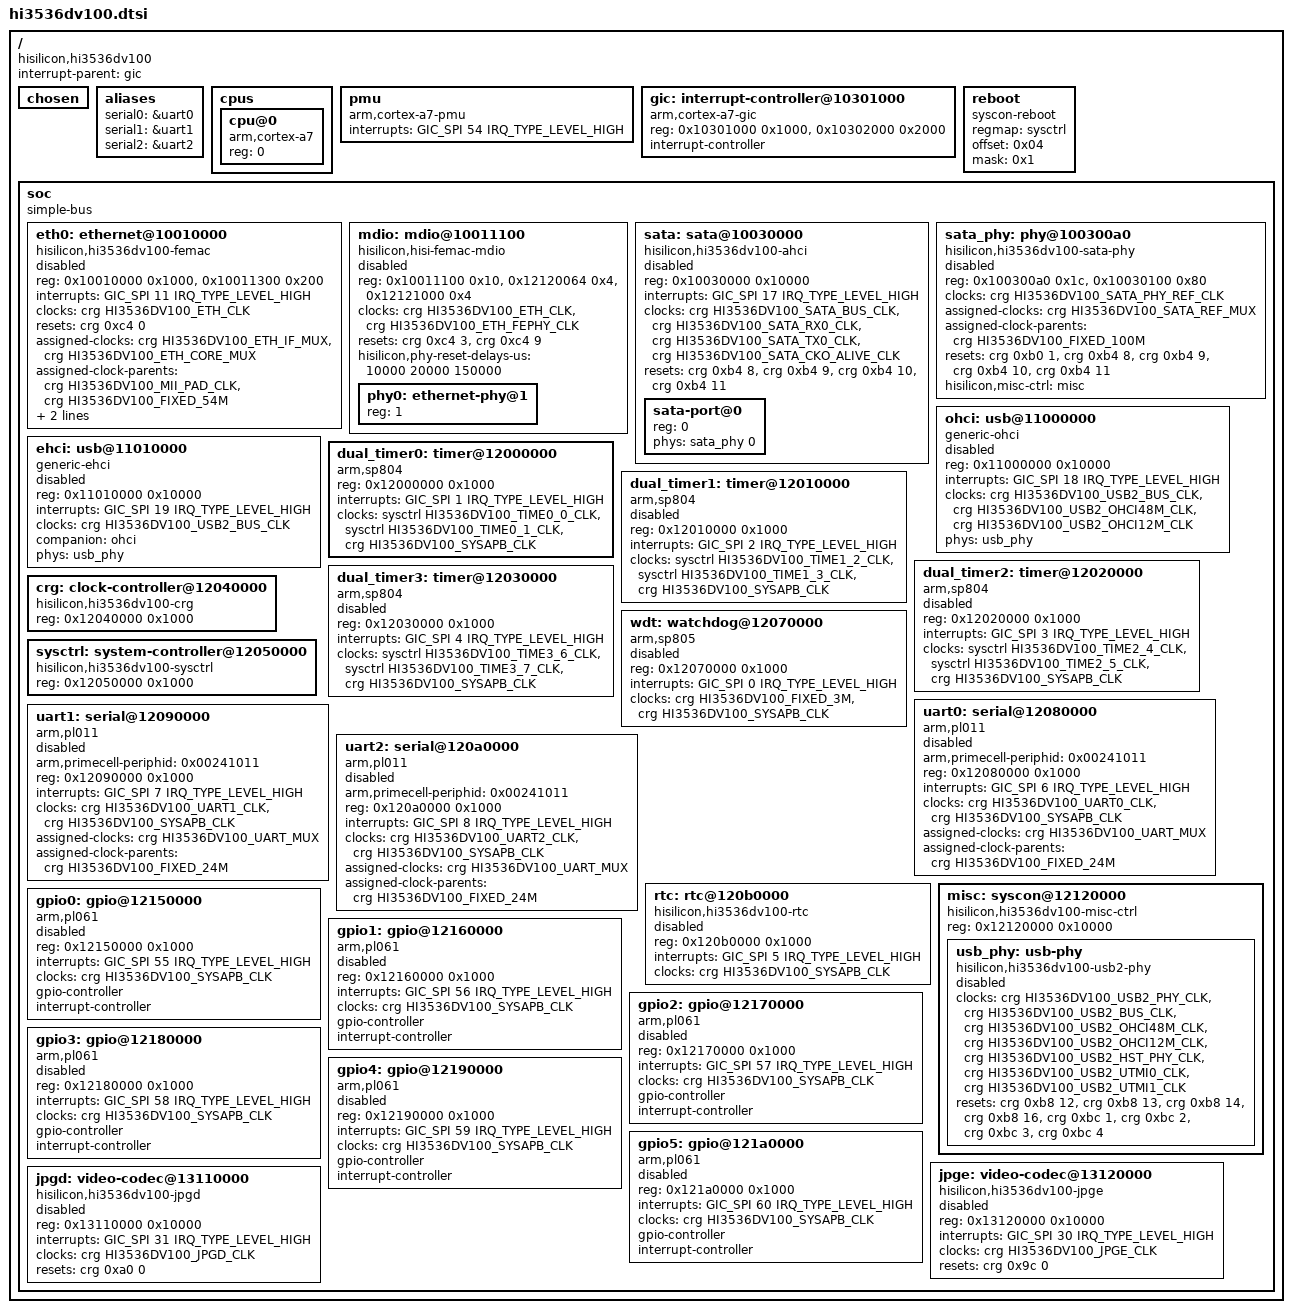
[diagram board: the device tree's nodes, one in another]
// SPDX-License-Identifier: GPL-2.0-or-later
/*
 * HiSilicon Hi3536D V100 SoC (NVR decoder, one Cortex-A7, GIC-400, DDR at
 * 0x80000000). The Hi3536E reports the same SCSYSID and is described by this
 * file too: the OpenIPC U-Boot sets other CPU and DDR PLL values for it and
 * reports SC_SYSID0 as 0x02000000 (a Hi3536D V100 board reads 0x01000000),
 * nothing else is known.
 *
 * Addresses and interrupts are those of the Hi3536D V100 data sheet (address
 * space mapping of chapter 2 and the interrupt table of chapter 3.4, where an
 * interrupt bit n is SPI n - 32). This file describes only the blocks that
 * have a binding and a driver and whose clocks and resets the CRG provides:
 * the other blocks (flash controller, DMA, media) follow with their
 * drivers, using the clock identifiers and reset bits of
 * hi3536dv100-clock.h.
 *
 * The Cortex-A7 generic timer is not described: no document gives the
 * frequency of its counter input, and on a Hi3536D V100 board CNTFRQ reads 0
 * and the counter stays at 0, so the SP804 timer is the only tick source.
 */

#include <dt-bindings/clock/hi3536dv100-clock.h>
#include <dt-bindings/interrupt-controller/arm-gic.h>

/ {
	compatible = "hisilicon,hi3536dv100";
	#address-cells = <1>;
	#size-cells = <1>;
	interrupt-parent = <&gic>;
	chosen { };

	aliases {
		serial0 = &uart0;
		serial1 = &uart1;
		serial2 = &uart2;
	};

	cpus {
		#address-cells = <1>;
		#size-cells = <0>;

		cpu@0 {
			device_type = "cpu";
			compatible = "arm,cortex-a7";
			reg = <0>;
		};
	};

	/* interrupt bit 86 (A7_PMUIRQ) */
	pmu {
		compatible = "arm,cortex-a7-pmu";
		interrupts = <GIC_SPI 54 IRQ_TYPE_LEVEL_HIGH>;
	};

	/* the GICC window is 0x2000 as in every GIC-400, the vendor tree maps 0x100 */
	gic: interrupt-controller@10301000 {
		compatible = "arm,cortex-a7-gic";
		reg = <0x10301000 0x1000>,	/* distributor */
		      <0x10302000 0x2000>;	/* CPU interface */
		#interrupt-cells = <3>;
		interrupt-controller;
	};

	/* SC_SYSRES is write protected by SC_LOCKEN */
	reboot {
		compatible = "syscon-reboot";
		regmap = <&sysctrl>;
		offset = <0x04>;	/* SC_SYSRES */
		mask = <0x1>;
	};

	soc {
		#address-cells = <1>;
		#size-cells = <1>;
		compatible = "simple-bus";
		ranges;

		/*
		 * The Fast Ethernet MAC (hisi-femac) with the MDIO controller, the
		 * internal FE PHY and the global MAC registers at +0x1300. The clock
		 * muxes are programmed here instead of relying on the boot loader:
		 * MII pads (the internal PHY is MII only) and the 54 MHz MAC core
		 * clock. The MDIO controller owns the PHY clock and the PHY reset;
		 * the internal/external PHY select (MISC_CTRL25 bit 5) is not set
		 * by this node, the MDIO driver handles it.
		 * A board that wires an external PHY replaces the PHY node, the
		 * phy-mode and the interface mux.
		 */
		eth0: ethernet@10010000 {
			compatible = "hisilicon,hi3536dv100-femac",
				     "hisilicon,hisi-femac-v2";
			reg = <0x10010000 0x1000>, <0x10011300 0x200>;
			interrupts = <GIC_SPI 11 IRQ_TYPE_LEVEL_HIGH>;
			clocks = <&crg HI3536DV100_ETH_CLK>;
			resets = <&crg 0xc4 0>;
			reset-names = "mac";
			assigned-clocks = <&crg HI3536DV100_ETH_IF_MUX>,
					  <&crg HI3536DV100_ETH_CORE_MUX>;
			assigned-clock-parents = <&crg HI3536DV100_MII_PAD_CLK>,
						 <&crg HI3536DV100_FIXED_54M>;
			phy-mode = "mii";
			phy-handle = <&phy0>;
			status = "disabled";
		};

		/*
		 * MDIO, then the control register of the internal PHY (MISC_CTRL25:
		 * bit 5 clear selects the internal PHY, bits 4:0 are its address) and its
		 * trim value (FEPHY_TRIM). The resets are PERI_CRG49 bit 3 (external
		 * PHY) and bit 9 (internal PHY); the driver resets and trims the
		 * internal PHY at probe time.
		 */
		mdio: mdio@10011100 {
			compatible = "hisilicon,hisi-femac-mdio";
			reg = <0x10011100 0x10>, <0x12120064 0x4>, <0x12121000 0x4>;
			clocks = <&crg HI3536DV100_ETH_CLK>,
				 <&crg HI3536DV100_ETH_FEPHY_CLK>;
			clock-names = "mdio", "phy";
			resets = <&crg 0xc4 3>, <&crg 0xc4 9>;
			reset-names = "external-phy", "internal-phy";
			hisilicon,phy-reset-delays-us = <10000 20000 150000>;
			#address-cells = <1>;
			#size-cells = <0>;
			status = "disabled";

			phy0: ethernet-phy@1 {
				reg = <1>;
			};
		};

		/*
		 * AHCI SATA controller with one port. The clocks and resets are
		 * those of PERI_CRG45, the PHY registers inside its window belong
		 * to the PHY node. The PI register may read 0xf: the sub-node of
		 * the port limits the implemented ports to port 0.
		 */
		sata: sata@10030000 {
			compatible = "hisilicon,hi3536dv100-ahci", "generic-ahci";
			reg = <0x10030000 0x10000>;
			interrupts = <GIC_SPI 17 IRQ_TYPE_LEVEL_HIGH>;
			clocks = <&crg HI3536DV100_SATA_BUS_CLK>,
				 <&crg HI3536DV100_SATA_RX0_CLK>,
				 <&crg HI3536DV100_SATA_TX0_CLK>,
				 <&crg HI3536DV100_SATA_CKO_ALIVE_CLK>;
			resets = <&crg 0xb4 8>, <&crg 0xb4 9>, <&crg 0xb4 10>,
				 <&crg 0xb4 11>;
			#address-cells = <1>;
			#size-cells = <0>;
			status = "disabled";

			sata-port@0 {
				reg = <0>;
				phys = <&sata_phy 0>;
			};
		};

		/*
		 * The PHY registers inside the AHCI window. The reference clock
		 * is 100 MHz, set here instead of relying on the boot loader
		 * (the register reads 100 MHz after a reset). The PHY pulses
		 * the four controller resets that it shares with the AHCI node.
		 */
		sata_phy: phy@100300a0 {
			compatible = "hisilicon,hi3536dv100-sata-phy";
			reg = <0x100300a0 0x1c>, <0x10030100 0x80>;
			reg-names = "ctrl", "ports";
			#phy-cells = <1>;
			clocks = <&crg HI3536DV100_SATA_PHY_REF_CLK>;
			clock-names = "ref";
			assigned-clocks = <&crg HI3536DV100_SATA_REF_MUX>;
			assigned-clock-parents = <&crg HI3536DV100_FIXED_100M>;
			resets = <&crg 0xb0 1>, <&crg 0xb4 8>, <&crg 0xb4 9>,
				 <&crg 0xb4 10>, <&crg 0xb4 11>;
			reset-names = "lane", "ctrl-bus", "ctrl-alive",
				      "ctrl-rx0", "ctrl-sata0";
			hisilicon,misc-ctrl = <&misc>;
			status = "disabled";
		};

		/*
		 * USB 2.0 host: one OHCI and one EHCI on two ports (the OHCI is the
		 * companion of the EHCI: full and low speed devices go to it). The clock
		 * gates, the resets and the start sequence belong to the PHY node (the
		 * MISC_CTRL child below); the controllers list the gates they run from. A
		 * board file enables the PHY and the controllers it wires.
		 */
		ohci: usb@11000000 {
			compatible = "generic-ohci";
			reg = <0x11000000 0x10000>;
			interrupts = <GIC_SPI 18 IRQ_TYPE_LEVEL_HIGH>;
			clocks = <&crg HI3536DV100_USB2_BUS_CLK>,
				 <&crg HI3536DV100_USB2_OHCI48M_CLK>,
				 <&crg HI3536DV100_USB2_OHCI12M_CLK>;
			phys = <&usb_phy>;
			phy-names = "usb";
			status = "disabled";
		};

		ehci: usb@11010000 {
			compatible = "generic-ehci";
			reg = <0x11010000 0x10000>;
			interrupts = <GIC_SPI 19 IRQ_TYPE_LEVEL_HIGH>;
			clocks = <&crg HI3536DV100_USB2_BUS_CLK>;
			companion = <&ohci>;
			phys = <&usb_phy>;
			phy-names = "usb";
			status = "disabled";
		};

		/*
		 * The four SP804 pairs: the count clocks are selected in SC_CTRL (3 MHz or
		 * the system APB clock) and provided by the system controller.
		 */
		dual_timer0: timer@12000000 {
			compatible = "arm,sp804", "arm,primecell";
			reg = <0x12000000 0x1000>;
			interrupts = <GIC_SPI 1 IRQ_TYPE_LEVEL_HIGH>;
			clocks = <&sysctrl HI3536DV100_TIME0_0_CLK>,
				 <&sysctrl HI3536DV100_TIME0_1_CLK>,
				 <&crg HI3536DV100_SYSAPB_CLK>;
			clock-names = "timer0", "timer1", "apb_pclk";
		};

		dual_timer1: timer@12010000 {
			compatible = "arm,sp804", "arm,primecell";
			reg = <0x12010000 0x1000>;
			interrupts = <GIC_SPI 2 IRQ_TYPE_LEVEL_HIGH>;
			clocks = <&sysctrl HI3536DV100_TIME1_2_CLK>,
				 <&sysctrl HI3536DV100_TIME1_3_CLK>,
				 <&crg HI3536DV100_SYSAPB_CLK>;
			clock-names = "timer2", "timer3", "apb_pclk";
			status = "disabled";
		};

		dual_timer2: timer@12020000 {
			compatible = "arm,sp804", "arm,primecell";
			reg = <0x12020000 0x1000>;
			interrupts = <GIC_SPI 3 IRQ_TYPE_LEVEL_HIGH>;
			clocks = <&sysctrl HI3536DV100_TIME2_4_CLK>,
				 <&sysctrl HI3536DV100_TIME2_5_CLK>,
				 <&crg HI3536DV100_SYSAPB_CLK>;
			clock-names = "timer4", "timer5", "apb_pclk";
			status = "disabled";
		};

		dual_timer3: timer@12030000 {
			compatible = "arm,sp804", "arm,primecell";
			reg = <0x12030000 0x1000>;
			interrupts = <GIC_SPI 4 IRQ_TYPE_LEVEL_HIGH>;
			clocks = <&sysctrl HI3536DV100_TIME3_6_CLK>,
				 <&sysctrl HI3536DV100_TIME3_7_CLK>,
				 <&crg HI3536DV100_SYSAPB_CLK>;
			clock-names = "timer6", "timer7", "apb_pclk";
			status = "disabled";
		};

		crg: clock-controller@12040000 {
			compatible = "hisilicon,hi3536dv100-crg";
			reg = <0x12040000 0x1000>;
			#clock-cells = <1>;
			#reset-cells = <2>;
		};

		/* SC_CTRL, SC_SYSRES (0x04), SC_SYSSTAT (0x8c), SC_SYSID0..3 (0xee0) */
		sysctrl: system-controller@12050000 {
			compatible = "hisilicon,hi3536dv100-sysctrl", "syscon";
			reg = <0x12050000 0x1000>;
			#clock-cells = <1>;
		};

		/* the watchdog counts a 3 MHz clock */
		wdt: watchdog@12070000 {
			compatible = "arm,sp805", "arm,primecell";
			reg = <0x12070000 0x1000>;
			interrupts = <GIC_SPI 0 IRQ_TYPE_LEVEL_HIGH>;
			clocks = <&crg HI3536DV100_FIXED_3M>,
				 <&crg HI3536DV100_SYSAPB_CLK>;
			clock-names = "wdog_clk", "apb_pclk";
			status = "disabled";
		};

		/*
		 * The three UARTs share the clock select of PERI_CRG51: it is set to the
		 * 24 MHz crystal here instead of relying on the boot loader.
		 */
		uart0: serial@12080000 {
			compatible = "arm,pl011", "arm,primecell";
			arm,primecell-periphid = <0x00241011>;
			reg = <0x12080000 0x1000>;
			interrupts = <GIC_SPI 6 IRQ_TYPE_LEVEL_HIGH>;
			clocks = <&crg HI3536DV100_UART0_CLK>,
				 <&crg HI3536DV100_SYSAPB_CLK>;
			clock-names = "uartclk", "apb_pclk";
			assigned-clocks = <&crg HI3536DV100_UART_MUX>;
			assigned-clock-parents = <&crg HI3536DV100_FIXED_24M>;
			status = "disabled";
		};

		uart1: serial@12090000 {
			compatible = "arm,pl011", "arm,primecell";
			arm,primecell-periphid = <0x00241011>;
			reg = <0x12090000 0x1000>;
			interrupts = <GIC_SPI 7 IRQ_TYPE_LEVEL_HIGH>;
			clocks = <&crg HI3536DV100_UART1_CLK>,
				 <&crg HI3536DV100_SYSAPB_CLK>;
			clock-names = "uartclk", "apb_pclk";
			assigned-clocks = <&crg HI3536DV100_UART_MUX>;
			assigned-clock-parents = <&crg HI3536DV100_FIXED_24M>;
			status = "disabled";
		};

		uart2: serial@120a0000 {
			compatible = "arm,pl011", "arm,primecell";
			arm,primecell-periphid = <0x00241011>;
			reg = <0x120a0000 0x1000>;
			interrupts = <GIC_SPI 8 IRQ_TYPE_LEVEL_HIGH>;
			clocks = <&crg HI3536DV100_UART2_CLK>,
				 <&crg HI3536DV100_SYSAPB_CLK>;
			clock-names = "uartclk", "apb_pclk";
			assigned-clocks = <&crg HI3536DV100_UART_MUX>;
			assigned-clock-parents = <&crg HI3536DV100_FIXED_24M>;
			status = "disabled";
		};

		/*
		 * The RTC macro sits behind an SPI bridge whose divider the driver
		 * derives from the system APB clock (the bridge clock is 5 MHz at
		 * most). The alarm interrupt is bit 37 of the interrupt table. The
		 * macro has its own supply pin (AVDD_BAT) and a 32.768 kHz crystal,
		 * so a board enables the node when it fits them.
		 */
		rtc: rtc@120b0000 {
			compatible = "hisilicon,hi3536dv100-rtc",
				     "hisilicon,hisi-spi-rtc-v3";
			reg = <0x120b0000 0x1000>;
			interrupts = <GIC_SPI 5 IRQ_TYPE_LEVEL_HIGH>;
			clocks = <&crg HI3536DV100_SYSAPB_CLK>;
			status = "disabled";
		};

		/*
		 * MISC_CTRL: the USB 2.0 control words and PHY registers (offset
		 * 0x8000) and the SATA PHY parameters now, the FE PHY controls and
		 * the DDR master priorities later.
		 */
		misc: syscon@12120000 {
			compatible = "hisilicon,hi3536dv100-misc-ctrl", "syscon", "simple-mfd";
			reg = <0x12120000 0x10000>;

			/*
			 * The start sequence drives PERI_CRG46 and PERI_CRG47 (reset bits
			 * 12 to 14 and 16 of 0xb8, 1 to 4 of 0xbc) and programs the
			 * controller control word, so nothing is left to the boot loader.
			 */
			usb_phy: usb-phy {
				compatible = "hisilicon,hi3536dv100-usb2-phy";
				#phy-cells = <0>;
				clocks = <&crg HI3536DV100_USB2_PHY_CLK>,
					 <&crg HI3536DV100_USB2_BUS_CLK>,
					 <&crg HI3536DV100_USB2_OHCI48M_CLK>,
					 <&crg HI3536DV100_USB2_OHCI12M_CLK>,
					 <&crg HI3536DV100_USB2_HST_PHY_CLK>,
					 <&crg HI3536DV100_USB2_UTMI0_CLK>,
					 <&crg HI3536DV100_USB2_UTMI1_CLK>;
				clock-names = "ref", "bus", "ohci48m", "ohci12m",
					      "hst-phy", "utmi0", "utmi1";
				resets = <&crg 0xb8 12>, <&crg 0xb8 13>,
					 <&crg 0xb8 14>, <&crg 0xb8 16>,
					 <&crg 0xbc 1>, <&crg 0xbc 2>,
					 <&crg 0xbc 3>, <&crg 0xbc 4>;
				reset-names = "bus", "utmi0", "utmi1", "hst-phy",
					      "phy", "port0-treq", "port1-treq",
					      "test";
				status = "disabled";
			};
		};

		gpio0: gpio@12150000 {
			compatible = "arm,pl061", "arm,primecell";
			reg = <0x12150000 0x1000>;
			interrupts = <GIC_SPI 55 IRQ_TYPE_LEVEL_HIGH>;
			clocks = <&crg HI3536DV100_SYSAPB_CLK>;
			clock-names = "apb_pclk";
			gpio-controller;
			#gpio-cells = <2>;
			interrupt-controller;
			#interrupt-cells = <2>;
			status = "disabled";
		};

		gpio1: gpio@12160000 {
			compatible = "arm,pl061", "arm,primecell";
			reg = <0x12160000 0x1000>;
			interrupts = <GIC_SPI 56 IRQ_TYPE_LEVEL_HIGH>;
			clocks = <&crg HI3536DV100_SYSAPB_CLK>;
			clock-names = "apb_pclk";
			gpio-controller;
			#gpio-cells = <2>;
			interrupt-controller;
			#interrupt-cells = <2>;
			status = "disabled";
		};

		gpio2: gpio@12170000 {
			compatible = "arm,pl061", "arm,primecell";
			reg = <0x12170000 0x1000>;
			interrupts = <GIC_SPI 57 IRQ_TYPE_LEVEL_HIGH>;
			clocks = <&crg HI3536DV100_SYSAPB_CLK>;
			clock-names = "apb_pclk";
			gpio-controller;
			#gpio-cells = <2>;
			interrupt-controller;
			#interrupt-cells = <2>;
			status = "disabled";
		};

		gpio3: gpio@12180000 {
			compatible = "arm,pl061", "arm,primecell";
			reg = <0x12180000 0x1000>;
			interrupts = <GIC_SPI 58 IRQ_TYPE_LEVEL_HIGH>;
			clocks = <&crg HI3536DV100_SYSAPB_CLK>;
			clock-names = "apb_pclk";
			gpio-controller;
			#gpio-cells = <2>;
			interrupt-controller;
			#interrupt-cells = <2>;
			status = "disabled";
		};

		gpio4: gpio@12190000 {
			compatible = "arm,pl061", "arm,primecell";
			reg = <0x12190000 0x1000>;
			interrupts = <GIC_SPI 59 IRQ_TYPE_LEVEL_HIGH>;
			clocks = <&crg HI3536DV100_SYSAPB_CLK>;
			clock-names = "apb_pclk";
			gpio-controller;
			#gpio-cells = <2>;
			interrupt-controller;
			#interrupt-cells = <2>;
			status = "disabled";
		};

		gpio5: gpio@121a0000 {
			compatible = "arm,pl061", "arm,primecell";
			reg = <0x121a0000 0x1000>;
			interrupts = <GIC_SPI 60 IRQ_TYPE_LEVEL_HIGH>;
			clocks = <&crg HI3536DV100_SYSAPB_CLK>;
			clock-names = "apb_pclk";
			gpio-controller;
			#gpio-cells = <2>;
			interrupt-controller;
			#interrupt-cells = <2>;
			status = "disabled";
		};

		/*
		 * Baseline JPEG encoder. Interrupt bit 62 (JPGE) is SPI 30. The
		 * gate and the soft reset are PERI_CRG39. Buffers come from the
		 * default CMA pool: a board that encodes large pictures needs a
		 * larger one.
		 */
		jpge: video-codec@13120000 {
			compatible = "hisilicon,hi3536dv100-jpge";
			reg = <0x13120000 0x10000>;
			interrupts = <GIC_SPI 30 IRQ_TYPE_LEVEL_HIGH>;
			clocks = <&crg HI3536DV100_JPGE_CLK>;
			resets = <&crg 0x9c 0>;
			status = "disabled";
		};

		/* JPEG decoder: gate and reset in PERI_CRG40, data sheet interrupt 63 */
		jpgd: video-codec@13110000 {
			compatible = "hisilicon,hi3536dv100-jpgd";
			reg = <0x13110000 0x10000>;
			interrupts = <GIC_SPI 31 IRQ_TYPE_LEVEL_HIGH>;
			clocks = <&crg HI3536DV100_JPGD_CLK>;
			resets = <&crg 0xa0 0>;
			status = "disabled";
		};
	};
};
